AUTOSAR XML (schema 4.0)
package /V/If
  sender receiver interface Cmd
    data req
  sender receiver interface Setpoint
    data value
  sender receiver interface BrakeReq
    data force
package /V/Swc
  application sw component type Telematics
    provide port CmdOut: provided-interface=Cmd
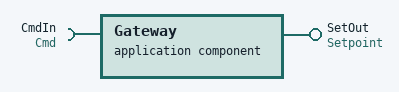
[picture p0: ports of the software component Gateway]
  application sw component type Gateway
    require port CmdIn: required-interface=Cmd
    provide port SetOut: provided-interface=Setpoint
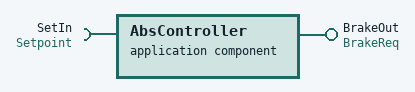
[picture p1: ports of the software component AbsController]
  application sw component type AbsController
    require port SetIn: required-interface=Setpoint
    provide port BrakeOut: provided-interface=BrakeReq
  sensor actuator sw component type BrakeActuator
    require port BrakeIn: required-interface=BrakeReq
  composition sw component type Veh
    4 x component:
      tel: type=Telematics
      gw: type=Gateway
      abs: type=AbsController
      brake: type=BrakeActuator
    connect tel.CmdOut -> gw.CmdIn
    connect gw.SetOut -> abs.SetIn
    connect abs.BrakeOut -> brake.BrakeIn
package /V/Comm
  pdu CmdIPdu
    signal CmdISig: system signal CmdSSig
  pdu SetIPdu
    signal SetISig: system signal SetSSig
  secured i pdu SetSecuredIPdu: auth-info-tx-length=32, freshness-value-id=2, freshness-value-length=8, payload=SetIPdu
package /V/Topology
  ecu instance TelematicsEcu
  ecu instance GatewayEcu
  ecu instance ChassisEcu
  system Veh
    root-software-compositions:
      root sw composition prototype Root: software-composition=Veh
    system mapping Map
      data-mappings:
        data-element=Root.CmdOut.req, system-signal=CmdSSig
        data-element=Root.SetOut.value, system-signal=SetSSig
      sw-mappings:
        swc to ecu mapping ToTelematics: component=tel, ecu-instance=TelematicsEcu
        swc to ecu mapping ToGateway: component=gw, ecu-instance=GatewayEcu
        swc to ecu mapping ToChassis: component=[abs, brake], ecu-instance=ChassisEcu
